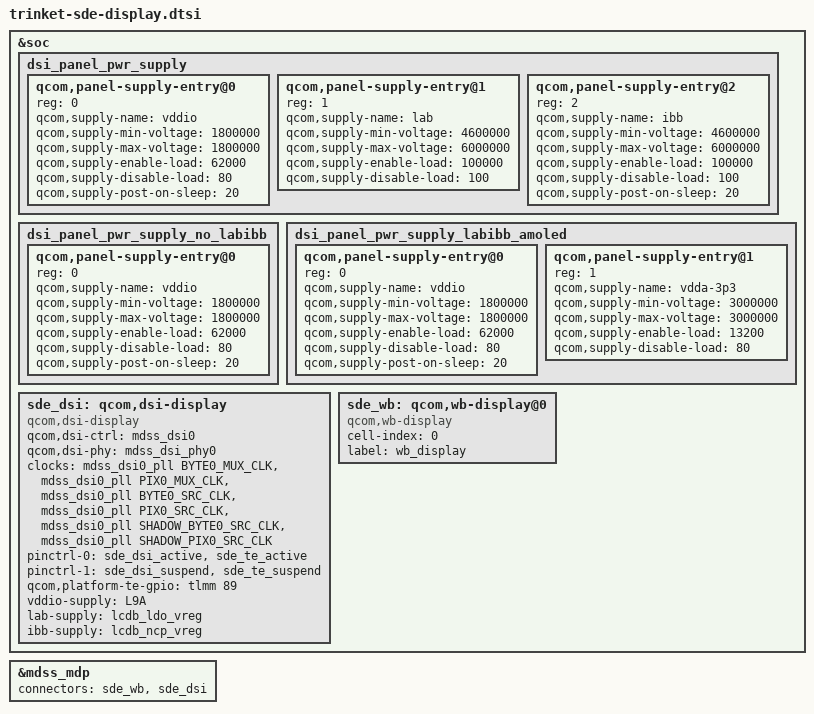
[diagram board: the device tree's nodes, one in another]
/* Copyright (c) 2019, The Linux Foundation. All rights reserved.
 *
 * This program is free software; you can redistribute it and/or modify
 * it under the terms of the GNU General Public License version 2 and
 * only version 2 as published by the Free Software Foundation.
 *
 * This program is distributed in the hope that it will be useful,
 * but WITHOUT ANY WARRANTY; without even the implied warranty of
 * MERCHANTABILITY or FITNESS FOR A PARTICULAR PURPOSE.  See the
 * GNU General Public License for more details.
 */

#include <dt-bindings/clock/mdss-14nm-pll-clk.h>

&soc {
	dsi_panel_pwr_supply: dsi_panel_pwr_supply {
		#address-cells = <1>;
		#size-cells = <0>;

		qcom,panel-supply-entry@0 {
			reg = <0>;
			qcom,supply-name = "vddio";
			qcom,supply-min-voltage = <1800000>;
			qcom,supply-max-voltage = <1800000>;
			qcom,supply-enable-load = <62000>;
			qcom,supply-disable-load = <80>;
			qcom,supply-post-on-sleep = <20>;
		};

		qcom,panel-supply-entry@1 {
			reg = <1>;
			qcom,supply-name = "lab";
			qcom,supply-min-voltage = <4600000>;
			qcom,supply-max-voltage = <6000000>;
			qcom,supply-enable-load = <100000>;
			qcom,supply-disable-load = <100>;
		};

		qcom,panel-supply-entry@2 {
			reg = <2>;
			qcom,supply-name = "ibb";
			qcom,supply-min-voltage = <4600000>;
			qcom,supply-max-voltage = <6000000>;
			qcom,supply-enable-load = <100000>;
			qcom,supply-disable-load = <100>;
			qcom,supply-post-on-sleep = <20>;
		};
	};

	dsi_panel_pwr_supply_no_labibb: dsi_panel_pwr_supply_no_labibb {
		#address-cells = <1>;
		#size-cells = <0>;

		qcom,panel-supply-entry@0 {
			reg = <0>;
			qcom,supply-name = "vddio";
			qcom,supply-min-voltage = <1800000>;
			qcom,supply-max-voltage = <1800000>;
			qcom,supply-enable-load = <62000>;
			qcom,supply-disable-load = <80>;
			qcom,supply-post-on-sleep = <20>;
		};
	};

	dsi_panel_pwr_supply_labibb_amoled: dsi_panel_pwr_supply_labibb_amoled {
		#address-cells = <1>;
		#size-cells = <0>;

		qcom,panel-supply-entry@0 {
			reg = <0>;
			qcom,supply-name = "vddio";
			qcom,supply-min-voltage = <1800000>;
			qcom,supply-max-voltage = <1800000>;
			qcom,supply-enable-load = <62000>;
			qcom,supply-disable-load = <80>;
			qcom,supply-post-on-sleep = <20>;
		};

		qcom,panel-supply-entry@1 {
			reg = <1>;
			qcom,supply-name = "vdda-3p3";
			qcom,supply-min-voltage = <3000000>;
			qcom,supply-max-voltage = <3000000>;
			qcom,supply-enable-load = <13200>;
			qcom,supply-disable-load = <80>;
		};
	};

	sde_dsi: qcom,dsi-display {
		compatible = "qcom,dsi-display";

		qcom,dsi-ctrl = <&mdss_dsi0>;
		qcom,dsi-phy = <&mdss_dsi_phy0>;

		clocks = <&mdss_dsi0_pll BYTE0_MUX_CLK>,
			 <&mdss_dsi0_pll PIX0_MUX_CLK>,
			 <&mdss_dsi0_pll BYTE0_SRC_CLK>,
			 <&mdss_dsi0_pll PIX0_SRC_CLK>,
			 <&mdss_dsi0_pll SHADOW_BYTE0_SRC_CLK>,
			 <&mdss_dsi0_pll SHADOW_PIX0_SRC_CLK>;
		clock-names = "mux_byte_clk0", "mux_pixel_clk0",
			"src_byte_clk0", "src_pixel_clk0",
			"shadow_byte_clk0", "shadow_pixel_clk0";
		pinctrl-names = "panel_active", "panel_suspend";
		pinctrl-0 = <&sde_dsi_active &sde_te_active>;
		pinctrl-1 = <&sde_dsi_suspend &sde_te_suspend>;

		qcom,platform-te-gpio = <&tlmm 89 0>;

		vddio-supply = <&L9A>;
		lab-supply = <&lcdb_ldo_vreg>;
		ibb-supply = <&lcdb_ncp_vreg>;
	};

	sde_wb: qcom,wb-display@0 {
		compatible = "qcom,wb-display";
		cell-index = <0>;
		label = "wb_display";
	};

};

&mdss_mdp {
	connectors = <&sde_wb &sde_dsi>;
};
